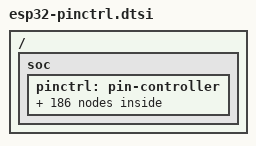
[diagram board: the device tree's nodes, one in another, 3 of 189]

/*
 * Copyright (c) 2022 Espressif Systems (Shanghai) Co., Ltd.
 *
 * SPDX-License-Identifier: Apache-2.0
 *
 * NOTE: Autogenerated file using esp_genpinctrl.py
 */

#include <dt-bindings/pinctrl/esp32-pinctrl.h>
#include <dt-bindings/pinctrl/esp32-gpio-sigmap.h>

/ {
	soc {
		pinctrl: pin-controller {

			/* UART0's RX pin states */
			uart0_rx_gpio0: uart0_rx_gpio0 {
				pinmux = <ESP32_PINMUX(0, ESP_U0RXD_IN, ESP_NOSIG)>;
				bias-pull-up;
				input-enable;
			};

			uart0_rx_gpio1: uart0_rx_gpio1 {
				pinmux = <ESP32_PINMUX(1, ESP_U0RXD_IN, ESP_NOSIG)>;
				bias-pull-up;
				input-enable;
			};

			uart0_rx_gpio2: uart0_rx_gpio2 {
				pinmux = <ESP32_PINMUX(2, ESP_U0RXD_IN, ESP_NOSIG)>;
				bias-pull-up;
				input-enable;
			};

			uart0_rx_gpio3: uart0_rx_gpio3 {
				pinmux = <ESP32_PINMUX(3, ESP_U0RXD_IN, ESP_NOSIG)>;
				bias-pull-up;
				input-enable;
			};

			uart0_rx_gpio4: uart0_rx_gpio4 {
				pinmux = <ESP32_PINMUX(4, ESP_U0RXD_IN, ESP_NOSIG)>;
				bias-pull-up;
				input-enable;
			};

			uart0_rx_gpio5: uart0_rx_gpio5 {
				pinmux = <ESP32_PINMUX(5, ESP_U0RXD_IN, ESP_NOSIG)>;
				bias-pull-up;
				input-enable;
			};

			uart0_rx_gpio6: uart0_rx_gpio6 {
				pinmux = <ESP32_PINMUX(6, ESP_U0RXD_IN, ESP_NOSIG)>;
				bias-pull-up;
				input-enable;
			};

			uart0_rx_gpio7: uart0_rx_gpio7 {
				pinmux = <ESP32_PINMUX(7, ESP_U0RXD_IN, ESP_NOSIG)>;
				bias-pull-up;
				input-enable;
			};

			uart0_rx_gpio8: uart0_rx_gpio8 {
				pinmux = <ESP32_PINMUX(8, ESP_U0RXD_IN, ESP_NOSIG)>;
				bias-pull-up;
				input-enable;
			};

			uart0_rx_gpio9: uart0_rx_gpio9 {
				pinmux = <ESP32_PINMUX(9, ESP_U0RXD_IN, ESP_NOSIG)>;
				bias-pull-up;
				input-enable;
			};

			uart0_rx_gpio10: uart0_rx_gpio10 {
				pinmux = <ESP32_PINMUX(10, ESP_U0RXD_IN, ESP_NOSIG)>;
				bias-pull-up;
				input-enable;
			};

			uart0_rx_gpio11: uart0_rx_gpio11 {
				pinmux = <ESP32_PINMUX(11, ESP_U0RXD_IN, ESP_NOSIG)>;
				bias-pull-up;
				input-enable;
			};

			uart0_rx_gpio12: uart0_rx_gpio12 {
				pinmux = <ESP32_PINMUX(12, ESP_U0RXD_IN, ESP_NOSIG)>;
				bias-pull-up;
				input-enable;
			};

			uart0_rx_gpio13: uart0_rx_gpio13 {
				pinmux = <ESP32_PINMUX(13, ESP_U0RXD_IN, ESP_NOSIG)>;
				bias-pull-up;
				input-enable;
			};

			uart0_rx_gpio14: uart0_rx_gpio14 {
				pinmux = <ESP32_PINMUX(14, ESP_U0RXD_IN, ESP_NOSIG)>;
				bias-pull-up;
				input-enable;
			};

			uart0_rx_gpio15: uart0_rx_gpio15 {
				pinmux = <ESP32_PINMUX(15, ESP_U0RXD_IN, ESP_NOSIG)>;
				bias-pull-up;
				input-enable;
			};

			uart0_rx_gpio16: uart0_rx_gpio16 {
				pinmux = <ESP32_PINMUX(16, ESP_U0RXD_IN, ESP_NOSIG)>;
				bias-pull-up;
				input-enable;
			};

			uart0_rx_gpio17: uart0_rx_gpio17 {
				pinmux = <ESP32_PINMUX(17, ESP_U0RXD_IN, ESP_NOSIG)>;
				bias-pull-up;
				input-enable;
			};

			uart0_rx_gpio18: uart0_rx_gpio18 {
				pinmux = <ESP32_PINMUX(18, ESP_U0RXD_IN, ESP_NOSIG)>;
				bias-pull-up;
				input-enable;
			};

			uart0_rx_gpio19: uart0_rx_gpio19 {
				pinmux = <ESP32_PINMUX(19, ESP_U0RXD_IN, ESP_NOSIG)>;
				bias-pull-up;
				input-enable;
			};

			uart0_rx_gpio21: uart0_rx_gpio21 {
				pinmux = <ESP32_PINMUX(21, ESP_U0RXD_IN, ESP_NOSIG)>;
				bias-pull-up;
				input-enable;
			};

			uart0_rx_gpio22: uart0_rx_gpio22 {
				pinmux = <ESP32_PINMUX(22, ESP_U0RXD_IN, ESP_NOSIG)>;
				bias-pull-up;
				input-enable;
			};

			uart0_rx_gpio23: uart0_rx_gpio23 {
				pinmux = <ESP32_PINMUX(23, ESP_U0RXD_IN, ESP_NOSIG)>;
				bias-pull-up;
				input-enable;
			};

			uart0_rx_gpio25: uart0_rx_gpio25 {
				pinmux = <ESP32_PINMUX(25, ESP_U0RXD_IN, ESP_NOSIG)>;
				bias-pull-up;
				input-enable;
			};

			uart0_rx_gpio26: uart0_rx_gpio26 {
				pinmux = <ESP32_PINMUX(26, ESP_U0RXD_IN, ESP_NOSIG)>;
				bias-pull-up;
				input-enable;
			};

			uart0_rx_gpio27: uart0_rx_gpio27 {
				pinmux = <ESP32_PINMUX(27, ESP_U0RXD_IN, ESP_NOSIG)>;
				bias-pull-up;
				input-enable;
			};

			uart0_rx_gpio32: uart0_rx_gpio32 {
				pinmux = <ESP32_PINMUX(32, ESP_U0RXD_IN, ESP_NOSIG)>;
				bias-pull-up;
				input-enable;
			};

			uart0_rx_gpio33: uart0_rx_gpio33 {
				pinmux = <ESP32_PINMUX(33, ESP_U0RXD_IN, ESP_NOSIG)>;
				bias-pull-up;
				input-enable;
			};

			uart0_rx_gpio34: uart0_rx_gpio34 {
				pinmux = <ESP32_PINMUX(34, ESP_U0RXD_IN, ESP_NOSIG)>;
				bias-pull-up;
				input-enable;
			};

			uart0_rx_gpio35: uart0_rx_gpio35 {
				pinmux = <ESP32_PINMUX(35, ESP_U0RXD_IN, ESP_NOSIG)>;
				bias-pull-up;
				input-enable;
			};

			uart0_rx_gpio36: uart0_rx_gpio36 {
				pinmux = <ESP32_PINMUX(36, ESP_U0RXD_IN, ESP_NOSIG)>;
				bias-pull-up;
				input-enable;
			};

			uart0_rx_gpio37: uart0_rx_gpio37 {
				pinmux = <ESP32_PINMUX(37, ESP_U0RXD_IN, ESP_NOSIG)>;
				bias-pull-up;
				input-enable;
			};

			uart0_rx_gpio38: uart0_rx_gpio38 {
				pinmux = <ESP32_PINMUX(38, ESP_U0RXD_IN, ESP_NOSIG)>;
				bias-pull-up;
				input-enable;
			};

			uart0_rx_gpio39: uart0_rx_gpio39 {
				pinmux = <ESP32_PINMUX(39, ESP_U0RXD_IN, ESP_NOSIG)>;
				bias-pull-up;
				input-enable;
			};

			/* UART0's TX pin states */
			uart0_tx_gpio0: uart0_tx_gpio0 {
				pinmux = <ESP32_PINMUX(0, ESP_NOSIG, ESP_U0TXD_OUT)>;
				output-enable;
			};

			uart0_tx_gpio1: uart0_tx_gpio1 {
				pinmux = <ESP32_PINMUX(1, ESP_NOSIG, ESP_U0TXD_OUT)>;
				output-enable;
			};

			uart0_tx_gpio2: uart0_tx_gpio2 {
				pinmux = <ESP32_PINMUX(2, ESP_NOSIG, ESP_U0TXD_OUT)>;
				output-enable;
			};

			uart0_tx_gpio3: uart0_tx_gpio3 {
				pinmux = <ESP32_PINMUX(3, ESP_NOSIG, ESP_U0TXD_OUT)>;
				output-enable;
			};

			uart0_tx_gpio4: uart0_tx_gpio4 {
				pinmux = <ESP32_PINMUX(4, ESP_NOSIG, ESP_U0TXD_OUT)>;
				output-enable;
			};

			uart0_tx_gpio5: uart0_tx_gpio5 {
				pinmux = <ESP32_PINMUX(5, ESP_NOSIG, ESP_U0TXD_OUT)>;
				output-enable;
			};

			uart0_tx_gpio6: uart0_tx_gpio6 {
				pinmux = <ESP32_PINMUX(6, ESP_NOSIG, ESP_U0TXD_OUT)>;
				output-enable;
			};

			uart0_tx_gpio7: uart0_tx_gpio7 {
				pinmux = <ESP32_PINMUX(7, ESP_NOSIG, ESP_U0TXD_OUT)>;
				output-enable;
			};

			uart0_tx_gpio8: uart0_tx_gpio8 {
				pinmux = <ESP32_PINMUX(8, ESP_NOSIG, ESP_U0TXD_OUT)>;
				output-enable;
			};

			uart0_tx_gpio9: uart0_tx_gpio9 {
				pinmux = <ESP32_PINMUX(9, ESP_NOSIG, ESP_U0TXD_OUT)>;
				output-enable;
			};

			uart0_tx_gpio10: uart0_tx_gpio10 {
				pinmux = <ESP32_PINMUX(10, ESP_NOSIG, ESP_U0TXD_OUT)>;
				output-enable;
			};

			uart0_tx_gpio11: uart0_tx_gpio11 {
				pinmux = <ESP32_PINMUX(11, ESP_NOSIG, ESP_U0TXD_OUT)>;
				output-enable;
			};

			uart0_tx_gpio12: uart0_tx_gpio12 {
				pinmux = <ESP32_PINMUX(12, ESP_NOSIG, ESP_U0TXD_OUT)>;
				output-enable;
			};

			uart0_tx_gpio13: uart0_tx_gpio13 {
				pinmux = <ESP32_PINMUX(13, ESP_NOSIG, ESP_U0TXD_OUT)>;
				output-enable;
			};

			uart0_tx_gpio14: uart0_tx_gpio14 {
				pinmux = <ESP32_PINMUX(14, ESP_NOSIG, ESP_U0TXD_OUT)>;
				output-enable;
			};

			uart0_tx_gpio15: uart0_tx_gpio15 {
				pinmux = <ESP32_PINMUX(15, ESP_NOSIG, ESP_U0TXD_OUT)>;
				output-enable;
			};

			uart0_tx_gpio16: uart0_tx_gpio16 {
				pinmux = <ESP32_PINMUX(16, ESP_NOSIG, ESP_U0TXD_OUT)>;
				output-enable;
			};

			uart0_tx_gpio17: uart0_tx_gpio17 {
				pinmux = <ESP32_PINMUX(17, ESP_NOSIG, ESP_U0TXD_OUT)>;
				output-enable;
			};

			uart0_tx_gpio18: uart0_tx_gpio18 {
				pinmux = <ESP32_PINMUX(18, ESP_NOSIG, ESP_U0TXD_OUT)>;
				output-enable;
			};

			uart0_tx_gpio19: uart0_tx_gpio19 {
				pinmux = <ESP32_PINMUX(19, ESP_NOSIG, ESP_U0TXD_OUT)>;
				output-enable;
			};

			uart0_tx_gpio21: uart0_tx_gpio21 {
				pinmux = <ESP32_PINMUX(21, ESP_NOSIG, ESP_U0TXD_OUT)>;
				output-enable;
			};

			uart0_tx_gpio22: uart0_tx_gpio22 {
				pinmux = <ESP32_PINMUX(22, ESP_NOSIG, ESP_U0TXD_OUT)>;
				output-enable;
			};

			uart0_tx_gpio23: uart0_tx_gpio23 {
				pinmux = <ESP32_PINMUX(23, ESP_NOSIG, ESP_U0TXD_OUT)>;
				output-enable;
			};

			uart0_tx_gpio25: uart0_tx_gpio25 {
				pinmux = <ESP32_PINMUX(25, ESP_NOSIG, ESP_U0TXD_OUT)>;
				output-enable;
			};

			uart0_tx_gpio26: uart0_tx_gpio26 {
				pinmux = <ESP32_PINMUX(26, ESP_NOSIG, ESP_U0TXD_OUT)>;
				output-enable;
			};

			uart0_tx_gpio27: uart0_tx_gpio27 {
				pinmux = <ESP32_PINMUX(27, ESP_NOSIG, ESP_U0TXD_OUT)>;
				output-enable;
			};

			uart0_tx_gpio32: uart0_tx_gpio32 {
				pinmux = <ESP32_PINMUX(32, ESP_NOSIG, ESP_U0TXD_OUT)>;
				output-enable;
			};

			uart0_tx_gpio33: uart0_tx_gpio33 {
				pinmux = <ESP32_PINMUX(33, ESP_NOSIG, ESP_U0TXD_OUT)>;
				output-enable;
			};

			/* UART1's RX pin states */
			uart1_rx_gpio0: uart1_rx_gpio0 {
				pinmux = <ESP32_PINMUX(0, ESP_U1RXD_IN, ESP_NOSIG)>;
				bias-pull-up;
				input-enable;
			};

			uart1_rx_gpio1: uart1_rx_gpio1 {
				pinmux = <ESP32_PINMUX(1, ESP_U1RXD_IN, ESP_NOSIG)>;
				bias-pull-up;
				input-enable;
			};

			uart1_rx_gpio2: uart1_rx_gpio2 {
				pinmux = <ESP32_PINMUX(2, ESP_U1RXD_IN, ESP_NOSIG)>;
				bias-pull-up;
				input-enable;
			};

			uart1_rx_gpio3: uart1_rx_gpio3 {
				pinmux = <ESP32_PINMUX(3, ESP_U1RXD_IN, ESP_NOSIG)>;
				bias-pull-up;
				input-enable;
			};

			uart1_rx_gpio4: uart1_rx_gpio4 {
				pinmux = <ESP32_PINMUX(4, ESP_U1RXD_IN, ESP_NOSIG)>;
				bias-pull-up;
				input-enable;
			};

			uart1_rx_gpio5: uart1_rx_gpio5 {
				pinmux = <ESP32_PINMUX(5, ESP_U1RXD_IN, ESP_NOSIG)>;
				bias-pull-up;
				input-enable;
			};

			uart1_rx_gpio6: uart1_rx_gpio6 {
				pinmux = <ESP32_PINMUX(6, ESP_U1RXD_IN, ESP_NOSIG)>;
				bias-pull-up;
				input-enable;
			};

			uart1_rx_gpio7: uart1_rx_gpio7 {
				pinmux = <ESP32_PINMUX(7, ESP_U1RXD_IN, ESP_NOSIG)>;
				bias-pull-up;
				input-enable;
			};

			uart1_rx_gpio8: uart1_rx_gpio8 {
				pinmux = <ESP32_PINMUX(8, ESP_U1RXD_IN, ESP_NOSIG)>;
				bias-pull-up;
				input-enable;
			};

			uart1_rx_gpio9: uart1_rx_gpio9 {
				pinmux = <ESP32_PINMUX(9, ESP_U1RXD_IN, ESP_NOSIG)>;
				bias-pull-up;
				input-enable;
			};

			uart1_rx_gpio10: uart1_rx_gpio10 {
				pinmux = <ESP32_PINMUX(10, ESP_U1RXD_IN, ESP_NOSIG)>;
				bias-pull-up;
				input-enable;
			};

			uart1_rx_gpio11: uart1_rx_gpio11 {
				pinmux = <ESP32_PINMUX(11, ESP_U1RXD_IN, ESP_NOSIG)>;
				bias-pull-up;
				input-enable;
			};

			uart1_rx_gpio12: uart1_rx_gpio12 {
				pinmux = <ESP32_PINMUX(12, ESP_U1RXD_IN, ESP_NOSIG)>;
				bias-pull-up;
				input-enable;
			};

			uart1_rx_gpio13: uart1_rx_gpio13 {
				pinmux = <ESP32_PINMUX(13, ESP_U1RXD_IN, ESP_NOSIG)>;
				bias-pull-up;
				input-enable;
			};

			uart1_rx_gpio14: uart1_rx_gpio14 {
				pinmux = <ESP32_PINMUX(14, ESP_U1RXD_IN, ESP_NOSIG)>;
				bias-pull-up;
				input-enable;
			};

			uart1_rx_gpio15: uart1_rx_gpio15 {
				pinmux = <ESP32_PINMUX(15, ESP_U1RXD_IN, ESP_NOSIG)>;
				bias-pull-up;
				input-enable;
			};

			uart1_rx_gpio16: uart1_rx_gpio16 {
				pinmux = <ESP32_PINMUX(16, ESP_U1RXD_IN, ESP_NOSIG)>;
				bias-pull-up;
				input-enable;
			};

			uart1_rx_gpio17: uart1_rx_gpio17 {
				pinmux = <ESP32_PINMUX(17, ESP_U1RXD_IN, ESP_NOSIG)>;
				bias-pull-up;
				input-enable;
			};

			uart1_rx_gpio18: uart1_rx_gpio18 {
				pinmux = <ESP32_PINMUX(18, ESP_U1RXD_IN, ESP_NOSIG)>;
				bias-pull-up;
				input-enable;
			};

			uart1_rx_gpio19: uart1_rx_gpio19 {
				pinmux = <ESP32_PINMUX(19, ESP_U1RXD_IN, ESP_NOSIG)>;
				bias-pull-up;
				input-enable;
			};

			uart1_rx_gpio21: uart1_rx_gpio21 {
				pinmux = <ESP32_PINMUX(21, ESP_U1RXD_IN, ESP_NOSIG)>;
				bias-pull-up;
				input-enable;
			};

			uart1_rx_gpio22: uart1_rx_gpio22 {
				pinmux = <ESP32_PINMUX(22, ESP_U1RXD_IN, ESP_NOSIG)>;
				bias-pull-up;
				input-enable;
			};

			uart1_rx_gpio23: uart1_rx_gpio23 {
				pinmux = <ESP32_PINMUX(23, ESP_U1RXD_IN, ESP_NOSIG)>;
				bias-pull-up;
				input-enable;
			};

			uart1_rx_gpio25: uart1_rx_gpio25 {
				pinmux = <ESP32_PINMUX(25, ESP_U1RXD_IN, ESP_NOSIG)>;
				bias-pull-up;
				input-enable;
			};

			uart1_rx_gpio26: uart1_rx_gpio26 {
				pinmux = <ESP32_PINMUX(26, ESP_U1RXD_IN, ESP_NOSIG)>;
				bias-pull-up;
				input-enable;
			};

			uart1_rx_gpio27: uart1_rx_gpio27 {
				pinmux = <ESP32_PINMUX(27, ESP_U1RXD_IN, ESP_NOSIG)>;
				bias-pull-up;
				input-enable;
			};

			uart1_rx_gpio32: uart1_rx_gpio32 {
				pinmux = <ESP32_PINMUX(32, ESP_U1RXD_IN, ESP_NOSIG)>;
				bias-pull-up;
				input-enable;
			};

			uart1_rx_gpio33: uart1_rx_gpio33 {
				pinmux = <ESP32_PINMUX(33, ESP_U1RXD_IN, ESP_NOSIG)>;
				bias-pull-up;
				input-enable;
			};

			uart1_rx_gpio34: uart1_rx_gpio34 {
				pinmux = <ESP32_PINMUX(34, ESP_U1RXD_IN, ESP_NOSIG)>;
				bias-pull-up;
				input-enable;
			};

			uart1_rx_gpio35: uart1_rx_gpio35 {
				pinmux = <ESP32_PINMUX(35, ESP_U1RXD_IN, ESP_NOSIG)>;
				bias-pull-up;
				input-enable;
			};

			uart1_rx_gpio36: uart1_rx_gpio36 {
				pinmux = <ESP32_PINMUX(36, ESP_U1RXD_IN, ESP_NOSIG)>;
				bias-pull-up;
				input-enable;
			};

			uart1_rx_gpio37: uart1_rx_gpio37 {
				pinmux = <ESP32_PINMUX(37, ESP_U1RXD_IN, ESP_NOSIG)>;
				bias-pull-up;
				input-enable;
			};

			uart1_rx_gpio38: uart1_rx_gpio38 {
				pinmux = <ESP32_PINMUX(38, ESP_U1RXD_IN, ESP_NOSIG)>;
				bias-pull-up;
				input-enable;
			};

			uart1_rx_gpio39: uart1_rx_gpio39 {
				pinmux = <ESP32_PINMUX(39, ESP_U1RXD_IN, ESP_NOSIG)>;
				bias-pull-up;
				input-enable;
			};

			/* UART1's TX pin states */
			uart1_tx_gpio0: uart1_tx_gpio0 {
				pinmux = <ESP32_PINMUX(0, ESP_NOSIG, ESP_U1TXD_OUT)>;
				output-enable;
			};

			uart1_tx_gpio1: uart1_tx_gpio1 {
				pinmux = <ESP32_PINMUX(1, ESP_NOSIG, ESP_U1TXD_OUT)>;
				output-enable;
			};

			uart1_tx_gpio2: uart1_tx_gpio2 {
				pinmux = <ESP32_PINMUX(2, ESP_NOSIG, ESP_U1TXD_OUT)>;
				output-enable;
			};

			uart1_tx_gpio3: uart1_tx_gpio3 {
				pinmux = <ESP32_PINMUX(3, ESP_NOSIG, ESP_U1TXD_OUT)>;
				output-enable;
			};

			uart1_tx_gpio4: uart1_tx_gpio4 {
				pinmux = <ESP32_PINMUX(4, ESP_NOSIG, ESP_U1TXD_OUT)>;
				output-enable;
			};

			uart1_tx_gpio5: uart1_tx_gpio5 {
				pinmux = <ESP32_PINMUX(5, ESP_NOSIG, ESP_U1TXD_OUT)>;
				output-enable;
			};

			uart1_tx_gpio6: uart1_tx_gpio6 {
				pinmux = <ESP32_PINMUX(6, ESP_NOSIG, ESP_U1TXD_OUT)>;
				output-enable;
			};

			uart1_tx_gpio7: uart1_tx_gpio7 {
				pinmux = <ESP32_PINMUX(7, ESP_NOSIG, ESP_U1TXD_OUT)>;
				output-enable;
			};

			uart1_tx_gpio8: uart1_tx_gpio8 {
				pinmux = <ESP32_PINMUX(8, ESP_NOSIG, ESP_U1TXD_OUT)>;
				output-enable;
			};

			uart1_tx_gpio9: uart1_tx_gpio9 {
				pinmux = <ESP32_PINMUX(9, ESP_NOSIG, ESP_U1TXD_OUT)>;
				output-enable;
			};

			uart1_tx_gpio10: uart1_tx_gpio10 {
				pinmux = <ESP32_PINMUX(10, ESP_NOSIG, ESP_U1TXD_OUT)>;
				output-enable;
			};

			uart1_tx_gpio11: uart1_tx_gpio11 {
				pinmux = <ESP32_PINMUX(11, ESP_NOSIG, ESP_U1TXD_OUT)>;
				output-enable;
			};

			uart1_tx_gpio12: uart1_tx_gpio12 {
				pinmux = <ESP32_PINMUX(12, ESP_NOSIG, ESP_U1TXD_OUT)>;
				output-enable;
			};

			uart1_tx_gpio13: uart1_tx_gpio13 {
				pinmux = <ESP32_PINMUX(13, ESP_NOSIG, ESP_U1TXD_OUT)>;
				output-enable;
			};

			uart1_tx_gpio14: uart1_tx_gpio14 {
				pinmux = <ESP32_PINMUX(14, ESP_NOSIG, ESP_U1TXD_OUT)>;
				output-enable;
			};

			uart1_tx_gpio15: uart1_tx_gpio15 {
				pinmux = <ESP32_PINMUX(15, ESP_NOSIG, ESP_U1TXD_OUT)>;
				output-enable;
			};

			uart1_tx_gpio16: uart1_tx_gpio16 {
				pinmux = <ESP32_PINMUX(16, ESP_NOSIG, ESP_U1TXD_OUT)>;
				output-enable;
			};

			uart1_tx_gpio17: uart1_tx_gpio17 {
				pinmux = <ESP32_PINMUX(17, ESP_NOSIG, ESP_U1TXD_OUT)>;
				output-enable;
			};

			uart1_tx_gpio18: uart1_tx_gpio18 {
				pinmux = <ESP32_PINMUX(18, ESP_NOSIG, ESP_U1TXD_OUT)>;
				output-enable;
			};

			uart1_tx_gpio19: uart1_tx_gpio19 {
				pinmux = <ESP32_PINMUX(19, ESP_NOSIG, ESP_U1TXD_OUT)>;
				output-enable;
			};

			uart1_tx_gpio21: uart1_tx_gpio21 {
				pinmux = <ESP32_PINMUX(21, ESP_NOSIG, ESP_U1TXD_OUT)>;
				output-enable;
			};

			uart1_tx_gpio22: uart1_tx_gpio22 {
				pinmux = <ESP32_PINMUX(22, ESP_NOSIG, ESP_U1TXD_OUT)>;
				output-enable;
			};

			uart1_tx_gpio23: uart1_tx_gpio23 {
				pinmux = <ESP32_PINMUX(23, ESP_NOSIG, ESP_U1TXD_OUT)>;
				output-enable;
			};

			uart1_tx_gpio25: uart1_tx_gpio25 {
				pinmux = <ESP32_PINMUX(25, ESP_NOSIG, ESP_U1TXD_OUT)>;
				output-enable;
			};

			uart1_tx_gpio26: uart1_tx_gpio26 {
				pinmux = <ESP32_PINMUX(26, ESP_NOSIG, ESP_U1TXD_OUT)>;
				output-enable;
			};

			uart1_tx_gpio27: uart1_tx_gpio27 {
				pinmux = <ESP32_PINMUX(27, ESP_NOSIG, ESP_U1TXD_OUT)>;
				output-enable;
			};

			uart1_tx_gpio32: uart1_tx_gpio32 {
				pinmux = <ESP32_PINMUX(32, ESP_NOSIG, ESP_U1TXD_OUT)>;
				output-enable;
			};

			uart1_tx_gpio33: uart1_tx_gpio33 {
				pinmux = <ESP32_PINMUX(33, ESP_NOSIG, ESP_U1TXD_OUT)>;
				output-enable;
			};

			/* UART2's RX pin states */
			uart2_rx_gpio0: uart2_rx_gpio0 {
				pinmux = <ESP32_PINMUX(0, ESP_U2RXD_IN, ESP_NOSIG)>;
				bias-pull-up;
				input-enable;
			};

			uart2_rx_gpio1: uart2_rx_gpio1 {
				pinmux = <ESP32_PINMUX(1, ESP_U2RXD_IN, ESP_NOSIG)>;
				bias-pull-up;
				input-enable;
			};

			uart2_rx_gpio2: uart2_rx_gpio2 {
				pinmux = <ESP32_PINMUX(2, ESP_U2RXD_IN, ESP_NOSIG)>;
				bias-pull-up;
				input-enable;
			};

			uart2_rx_gpio3: uart2_rx_gpio3 {
				pinmux = <ESP32_PINMUX(3, ESP_U2RXD_IN, ESP_NOSIG)>;
				bias-pull-up;
				input-enable;
			};

			uart2_rx_gpio4: uart2_rx_gpio4 {
				pinmux = <ESP32_PINMUX(4, ESP_U2RXD_IN, ESP_NOSIG)>;
				bias-pull-up;
				input-enable;
			};

			uart2_rx_gpio5: uart2_rx_gpio5 {
				pinmux = <ESP32_PINMUX(5, ESP_U2RXD_IN, ESP_NOSIG)>;
				bias-pull-up;
				input-enable;
			};

			uart2_rx_gpio6: uart2_rx_gpio6 {
				pinmux = <ESP32_PINMUX(6, ESP_U2RXD_IN, ESP_NOSIG)>;
				bias-pull-up;
				input-enable;
			};

			uart2_rx_gpio7: uart2_rx_gpio7 {
				pinmux = <ESP32_PINMUX(7, ESP_U2RXD_IN, ESP_NOSIG)>;
				bias-pull-up;
				input-enable;
			};

			uart2_rx_gpio8: uart2_rx_gpio8 {
				pinmux = <ESP32_PINMUX(8, ESP_U2RXD_IN, ESP_NOSIG)>;
				bias-pull-up;
				input-enable;
			};

			uart2_rx_gpio9: uart2_rx_gpio9 {
				pinmux = <ESP32_PINMUX(9, ESP_U2RXD_IN, ESP_NOSIG)>;
				bias-pull-up;
				input-enable;
			};

			uart2_rx_gpio10: uart2_rx_gpio10 {
				pinmux = <ESP32_PINMUX(10, ESP_U2RXD_IN, ESP_NOSIG)>;
				bias-pull-up;
				input-enable;
			};

			uart2_rx_gpio11: uart2_rx_gpio11 {
				pinmux = <ESP32_PINMUX(11, ESP_U2RXD_IN, ESP_NOSIG)>;
				bias-pull-up;
				input-enable;
			};

			uart2_rx_gpio12: uart2_rx_gpio12 {
				pinmux = <ESP32_PINMUX(12, ESP_U2RXD_IN, ESP_NOSIG)>;
				bias-pull-up;
				input-enable;
			};

			uart2_rx_gpio13: uart2_rx_gpio13 {
				pinmux = <ESP32_PINMUX(13, ESP_U2RXD_IN, ESP_NOSIG)>;
				bias-pull-up;
				input-enable;
			};

			uart2_rx_gpio14: uart2_rx_gpio14 {
				pinmux = <ESP32_PINMUX(14, ESP_U2RXD_IN, ESP_NOSIG)>;
				bias-pull-up;
				input-enable;
			};

			uart2_rx_gpio15: uart2_rx_gpio15 {
				pinmux = <ESP32_PINMUX(15, ESP_U2RXD_IN, ESP_NOSIG)>;
				bias-pull-up;
				input-enable;
			};

			uart2_rx_gpio16: uart2_rx_gpio16 {
				pinmux = <ESP32_PINMUX(16, ESP_U2RXD_IN, ESP_NOSIG)>;
				bias-pull-up;
				input-enable;
			};

			uart2_rx_gpio17: uart2_rx_gpio17 {
				pinmux = <ESP32_PINMUX(17, ESP_U2RXD_IN, ESP_NOSIG)>;
				bias-pull-up;
				input-enable;
			};

			uart2_rx_gpio18: uart2_rx_gpio18 {
				pinmux = <ESP32_PINMUX(18, ESP_U2RXD_IN, ESP_NOSIG)>;
				bias-pull-up;
				input-enable;
			};

			uart2_rx_gpio19: uart2_rx_gpio19 {
				pinmux = <ESP32_PINMUX(19, ESP_U2RXD_IN, ESP_NOSIG)>;
				bias-pull-up;
				input-enable;
			};

			uart2_rx_gpio21: uart2_rx_gpio21 {
				pinmux = <ESP32_PINMUX(21, ESP_U2RXD_IN, ESP_NOSIG)>;
				bias-pull-up;
				input-enable;
			};

			uart2_rx_gpio22: uart2_rx_gpio22 {
				pinmux = <ESP32_PINMUX(22, ESP_U2RXD_IN, ESP_NOSIG)>;
				bias-pull-up;
				input-enable;
			};

			uart2_rx_gpio23: uart2_rx_gpio23 {
				pinmux = <ESP32_PINMUX(23, ESP_U2RXD_IN, ESP_NOSIG)>;
				bias-pull-up;
				input-enable;
			};

			uart2_rx_gpio25: uart2_rx_gpio25 {
				pinmux = <ESP32_PINMUX(25, ESP_U2RXD_IN, ESP_NOSIG)>;
				bias-pull-up;
				input-enable;
			};

			uart2_rx_gpio26: uart2_rx_gpio26 {
				pinmux = <ESP32_PINMUX(26, ESP_U2RXD_IN, ESP_NOSIG)>;
				bias-pull-up;
				input-enable;
			};

			uart2_rx_gpio27: uart2_rx_gpio27 {
				pinmux = <ESP32_PINMUX(27, ESP_U2RXD_IN, ESP_NOSIG)>;
				bias-pull-up;
				input-enable;
			};

			uart2_rx_gpio32: uart2_rx_gpio32 {
				pinmux = <ESP32_PINMUX(32, ESP_U2RXD_IN, ESP_NOSIG)>;
				bias-pull-up;
				input-enable;
			};

			uart2_rx_gpio33: uart2_rx_gpio33 {
				pinmux = <ESP32_PINMUX(33, ESP_U2RXD_IN, ESP_NOSIG)>;
				bias-pull-up;
				input-enable;
			};

			uart2_rx_gpio34: uart2_rx_gpio34 {
				pinmux = <ESP32_PINMUX(34, ESP_U2RXD_IN, ESP_NOSIG)>;
				bias-pull-up;
				input-enable;
			};

			uart2_rx_gpio35: uart2_rx_gpio35 {
				pinmux = <ESP32_PINMUX(35, ESP_U2RXD_IN, ESP_NOSIG)>;
				bias-pull-up;
				input-enable;
			};

			uart2_rx_gpio36: uart2_rx_gpio36 {
				pinmux = <ESP32_PINMUX(36, ESP_U2RXD_IN, ESP_NOSIG)>;
				bias-pull-up;
				input-enable;
			};

			uart2_rx_gpio37: uart2_rx_gpio37 {
				pinmux = <ESP32_PINMUX(37, ESP_U2RXD_IN, ESP_NOSIG)>;
				bias-pull-up;
				input-enable;
			};

			uart2_rx_gpio38: uart2_rx_gpio38 {
				pinmux = <ESP32_PINMUX(38, ESP_U2RXD_IN, ESP_NOSIG)>;
				bias-pull-up;
				input-enable;
			};

			uart2_rx_gpio39: uart2_rx_gpio39 {
				pinmux = <ESP32_PINMUX(39, ESP_U2RXD_IN, ESP_NOSIG)>;
				bias-pull-up;
				input-enable;
			};

			/* UART2's TX pin states */
			uart2_tx_gpio0: uart2_tx_gpio0 {
				pinmux = <ESP32_PINMUX(0, ESP_NOSIG, ESP_U2TXD_OUT)>;
				output-enable;
			};

			uart2_tx_gpio1: uart2_tx_gpio1 {
				pinmux = <ESP32_PINMUX(1, ESP_NOSIG, ESP_U2TXD_OUT)>;
				output-enable;
			};

			uart2_tx_gpio2: uart2_tx_gpio2 {
				pinmux = <ESP32_PINMUX(2, ESP_NOSIG, ESP_U2TXD_OUT)>;
				output-enable;
			};

			uart2_tx_gpio3: uart2_tx_gpio3 {
				pinmux = <ESP32_PINMUX(3, ESP_NOSIG, ESP_U2TXD_OUT)>;
				output-enable;
			};

			uart2_tx_gpio4: uart2_tx_gpio4 {
				pinmux = <ESP32_PINMUX(4, ESP_NOSIG, ESP_U2TXD_OUT)>;
				output-enable;
			};

			uart2_tx_gpio5: uart2_tx_gpio5 {
				pinmux = <ESP32_PINMUX(5, ESP_NOSIG, ESP_U2TXD_OUT)>;
				output-enable;
			};

			uart2_tx_gpio6: uart2_tx_gpio6 {
				pinmux = <ESP32_PINMUX(6, ESP_NOSIG, ESP_U2TXD_OUT)>;
				output-enable;
			};

			uart2_tx_gpio7: uart2_tx_gpio7 {
				pinmux = <ESP32_PINMUX(7, ESP_NOSIG, ESP_U2TXD_OUT)>;
				output-enable;
			};

			uart2_tx_gpio8: uart2_tx_gpio8 {
				pinmux = <ESP32_PINMUX(8, ESP_NOSIG, ESP_U2TXD_OUT)>;
				output-enable;
			};

			uart2_tx_gpio9: uart2_tx_gpio9 {
				pinmux = <ESP32_PINMUX(9, ESP_NOSIG, ESP_U2TXD_OUT)>;
				output-enable;
			};

			uart2_tx_gpio10: uart2_tx_gpio10 {
				pinmux = <ESP32_PINMUX(10, ESP_NOSIG, ESP_U2TXD_OUT)>;
				output-enable;
			};

			uart2_tx_gpio11: uart2_tx_gpio11 {
				pinmux = <ESP32_PINMUX(11, ESP_NOSIG, ESP_U2TXD_OUT)>;
				output-enable;
			};

			uart2_tx_gpio12: uart2_tx_gpio12 {
				pinmux = <ESP32_PINMUX(12, ESP_NOSIG, ESP_U2TXD_OUT)>;
				output-enable;
			};

			uart2_tx_gpio13: uart2_tx_gpio13 {
				pinmux = <ESP32_PINMUX(13, ESP_NOSIG, ESP_U2TXD_OUT)>;
				output-enable;
			};

			uart2_tx_gpio14: uart2_tx_gpio14 {
				pinmux = <ESP32_PINMUX(14, ESP_NOSIG, ESP_U2TXD_OUT)>;
				output-enable;
			};

			uart2_tx_gpio15: uart2_tx_gpio15 {
				pinmux = <ESP32_PINMUX(15, ESP_NOSIG, ESP_U2TXD_OUT)>;
				output-enable;
			};

			uart2_tx_gpio16: uart2_tx_gpio16 {
				pinmux = <ESP32_PINMUX(16, ESP_NOSIG, ESP_U2TXD_OUT)>;
				output-enable;
			};

			uart2_tx_gpio17: uart2_tx_gpio17 {
				pinmux = <ESP32_PINMUX(17, ESP_NOSIG, ESP_U2TXD_OUT)>;
				output-enable;
			};

			uart2_tx_gpio18: uart2_tx_gpio18 {
				pinmux = <ESP32_PINMUX(18, ESP_NOSIG, ESP_U2TXD_OUT)>;
				output-enable;
			};

			uart2_tx_gpio19: uart2_tx_gpio19 {
				pinmux = <ESP32_PINMUX(19, ESP_NOSIG, ESP_U2TXD_OUT)>;
				output-enable;
			};

			uart2_tx_gpio21: uart2_tx_gpio21 {
				pinmux = <ESP32_PINMUX(21, ESP_NOSIG, ESP_U2TXD_OUT)>;
				output-enable;
			};

			uart2_tx_gpio22: uart2_tx_gpio22 {
				pinmux = <ESP32_PINMUX(22, ESP_NOSIG, ESP_U2TXD_OUT)>;
				output-enable;
			};

			uart2_tx_gpio23: uart2_tx_gpio23 {
				pinmux = <ESP32_PINMUX(23, ESP_NOSIG, ESP_U2TXD_OUT)>;
				output-enable;
			};

			uart2_tx_gpio25: uart2_tx_gpio25 {
				pinmux = <ESP32_PINMUX(25, ESP_NOSIG, ESP_U2TXD_OUT)>;
				output-enable;
			};

			uart2_tx_gpio26: uart2_tx_gpio26 {
				pinmux = <ESP32_PINMUX(26, ESP_NOSIG, ESP_U2TXD_OUT)>;
				output-enable;
			};

			uart2_tx_gpio27: uart2_tx_gpio27 {
				pinmux = <ESP32_PINMUX(27, ESP_NOSIG, ESP_U2TXD_OUT)>;
				output-enable;
			};

			uart2_tx_gpio32: uart2_tx_gpio32 {
				pinmux = <ESP32_PINMUX(32, ESP_NOSIG, ESP_U2TXD_OUT)>;
				output-enable;
			};

			uart2_tx_gpio33: uart2_tx_gpio33 {
				pinmux = <ESP32_PINMUX(33, ESP_NOSIG, ESP_U2TXD_OUT)>;
				output-enable;
			};

		};
	};
};
